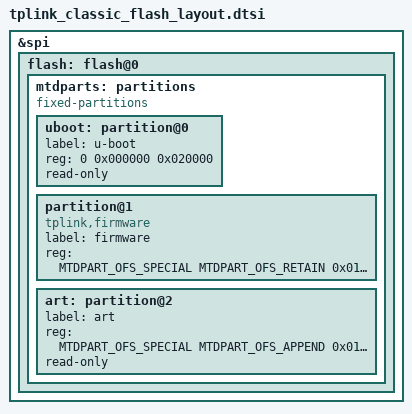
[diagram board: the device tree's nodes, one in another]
// SPDX-License-Identifier: GPL-2.0-or-later OR MIT

#include <dt-bindings/mtd/partitions/constants.h>

&spi {
	flash: flash@0 {
		mtdparts: partitions {
			compatible = "fixed-partitions";
			#address-cells = <2>;
			#size-cells = <1>;

			uboot: partition@0 {
				label = "u-boot";
				reg = <0 0x000000 0x020000>;
				read-only;
			};

			partition@1 {
				compatible = "tplink,firmware";
				label = "firmware";
				// retain 0x10000
				reg = <MTDPART_OFS_SPECIAL MTDPART_OFS_RETAIN 0x010000>;
			};

			art: partition@2 {
				label = "art";
				reg = <MTDPART_OFS_SPECIAL MTDPART_OFS_APPEND 0x010000>;
				read-only;
			};
		};
	};
};
